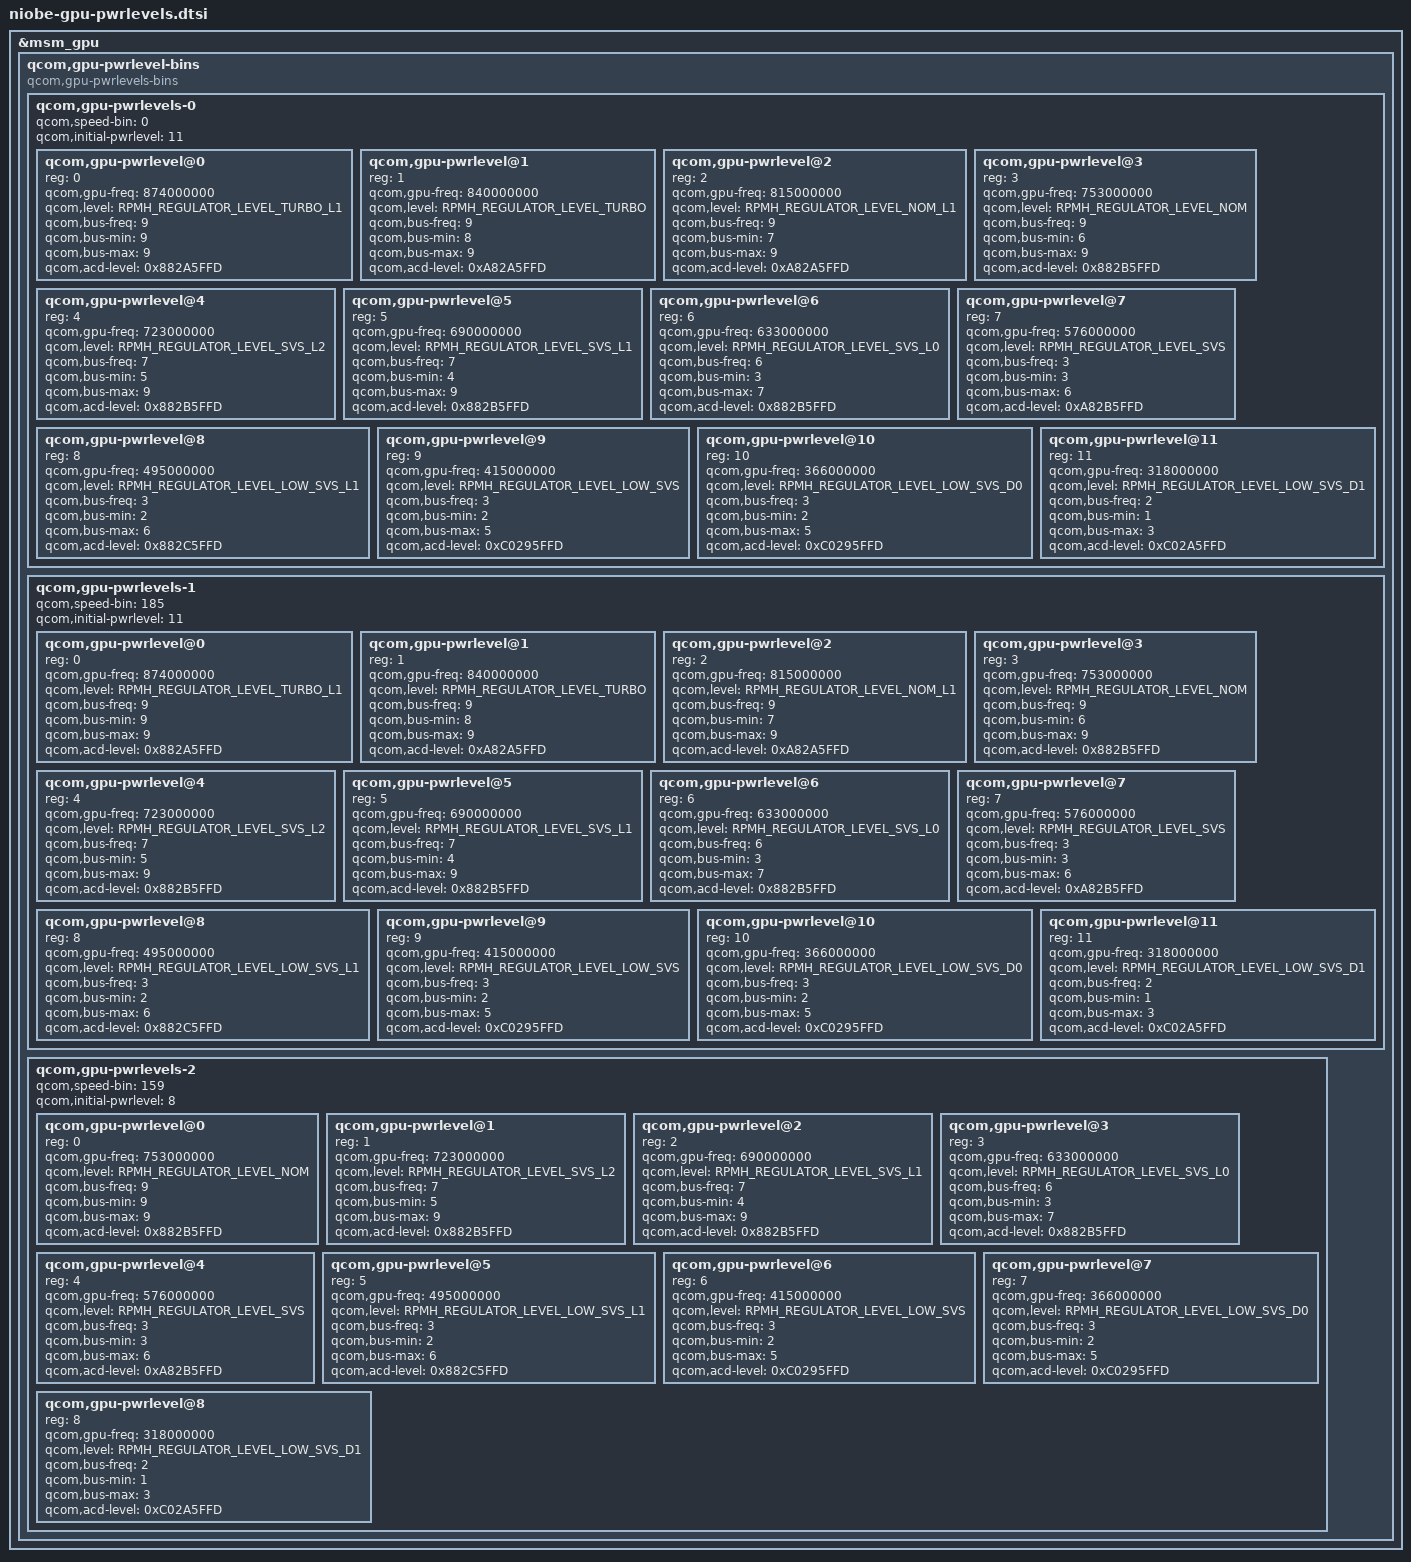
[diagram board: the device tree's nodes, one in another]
&msm_gpu {
	/* Power levels */
	qcom,gpu-pwrlevel-bins {
		#address-cells = <1>;
		#size-cells = <0>;

		compatible = "qcom,gpu-pwrlevels-bins";

		qcom,gpu-pwrlevels-0 {
			#address-cells = <1>;
			#size-cells = <0>;

			qcom,speed-bin = <0>;
			qcom,initial-pwrlevel = <11>;

			/* TURBO_L1 */
			qcom,gpu-pwrlevel@0 {
				reg = <0>;
				qcom,gpu-freq = <874000000>;
				qcom,level = <RPMH_REGULATOR_LEVEL_TURBO_L1>;

				qcom,bus-freq = <9>;
				qcom,bus-min = <9>;
				qcom,bus-max = <9>;

				qcom,acd-level = <0x882A5FFD>;
			};

			/* TURBO */
			qcom,gpu-pwrlevel@1 {
				reg = <1>;
				qcom,gpu-freq = <840000000>;
				qcom,level = <RPMH_REGULATOR_LEVEL_TURBO>;

				qcom,bus-freq = <9>;
				qcom,bus-min = <8>;
				qcom,bus-max = <9>;

				qcom,acd-level = <0xA82A5FFD>;
			};

			/* NOM_L1 */
			qcom,gpu-pwrlevel@2 {
				reg = <2>;
				qcom,gpu-freq = <815000000>;
				qcom,level = <RPMH_REGULATOR_LEVEL_NOM_L1>;

				qcom,bus-freq = <9>;
				qcom,bus-min = <7>;
				qcom,bus-max = <9>;

				qcom,acd-level = <0xA82A5FFD>;
			};

			/* NOM */
			qcom,gpu-pwrlevel@3 {
				reg = <3>;
				qcom,gpu-freq = <753000000>;
				qcom,level = <RPMH_REGULATOR_LEVEL_NOM>;

				qcom,bus-freq = <9>;
				qcom,bus-min = <6>;
				qcom,bus-max = <9>;

				qcom,acd-level = <0x882B5FFD>;
			};

			/* SVS_L2 */
			qcom,gpu-pwrlevel@4 {
				reg = <4>;
				qcom,gpu-freq = <723000000>;
				qcom,level = <RPMH_REGULATOR_LEVEL_SVS_L2>;

				qcom,bus-freq = <7>;
				qcom,bus-min = <5>;
				qcom,bus-max = <9>;

				qcom,acd-level = <0x882B5FFD>;
			};

			/* SVS_L1 */
			qcom,gpu-pwrlevel@5 {
				reg = <5>;
				qcom,gpu-freq = <690000000>;
				qcom,level = <RPMH_REGULATOR_LEVEL_SVS_L1>;

				qcom,bus-freq = <7>;
				qcom,bus-min = <4>;
				qcom,bus-max = <9>;

				qcom,acd-level = <0x882B5FFD>;
			};

			/* SVS_L0 */
			qcom,gpu-pwrlevel@6 {
				reg = <6>;
				qcom,gpu-freq = <633000000>;
				qcom,level = <RPMH_REGULATOR_LEVEL_SVS_L0>;

				qcom,bus-freq = <6>;
				qcom,bus-min = <3>;
				qcom,bus-max = <7>;

				qcom,acd-level = <0x882B5FFD>;
			};

			/* SVS */
			qcom,gpu-pwrlevel@7 {
				reg = <7>;
				qcom,gpu-freq = <576000000>;
				qcom,level = <RPMH_REGULATOR_LEVEL_SVS>;

				qcom,bus-freq = <3>;
				qcom,bus-min = <3>;
				qcom,bus-max = <6>;

				qcom,acd-level = <0xA82B5FFD>;
			};

			/* Low_SVS_L1 */
			qcom,gpu-pwrlevel@8 {
				reg = <8>;
				qcom,gpu-freq = <495000000>;
				qcom,level = <RPMH_REGULATOR_LEVEL_LOW_SVS_L1>;

				qcom,bus-freq = <3>;
				qcom,bus-min = <2>;
				qcom,bus-max = <6>;

				qcom,acd-level = <0x882C5FFD>;
			};

			/* Low_SVS */
			qcom,gpu-pwrlevel@9 {
				reg = <9>;
				qcom,gpu-freq = <415000000>;
				qcom,level = <RPMH_REGULATOR_LEVEL_LOW_SVS>;

				qcom,bus-freq = <3>;
				qcom,bus-min = <2>;
				qcom,bus-max = <5>;

				qcom,acd-level = <0xC0295FFD>;
			};

			/* Low_SVS_D0 */
			qcom,gpu-pwrlevel@10 {
				reg = <10>;
				qcom,gpu-freq = <366000000>;
				qcom,level = <RPMH_REGULATOR_LEVEL_LOW_SVS_D0>;

				qcom,bus-freq = <3>;
				qcom,bus-min = <2>;
				qcom,bus-max = <5>;

				qcom,acd-level = <0xC0295FFD>;
			};

			/* Low_SVS_D1 */
			qcom,gpu-pwrlevel@11 {
				reg = <11>;
				qcom,gpu-freq = <318000000>;
				qcom,level = <RPMH_REGULATOR_LEVEL_LOW_SVS_D1>;

				qcom,bus-freq = <2>;
				qcom,bus-min = <1>;
				qcom,bus-max = <3>;

				qcom,acd-level = <0xC02A5FFD>;
			};
		};

		qcom,gpu-pwrlevels-1 {
			#address-cells = <1>;
			#size-cells = <0>;

			qcom,speed-bin = <185>;
			qcom,initial-pwrlevel = <11>;

			/* TURBO_L1 */
			qcom,gpu-pwrlevel@0 {
				reg = <0>;
				qcom,gpu-freq = <874000000>;
				qcom,level = <RPMH_REGULATOR_LEVEL_TURBO_L1>;

				qcom,bus-freq = <9>;
				qcom,bus-min = <9>;
				qcom,bus-max = <9>;

				qcom,acd-level = <0x882A5FFD>;
			};

			/* TURBO */
			qcom,gpu-pwrlevel@1 {
				reg = <1>;
				qcom,gpu-freq = <840000000>;
				qcom,level = <RPMH_REGULATOR_LEVEL_TURBO>;

				qcom,bus-freq = <9>;
				qcom,bus-min = <8>;
				qcom,bus-max = <9>;

				qcom,acd-level = <0xA82A5FFD>;
			};

			/* NOM_L1 */
			qcom,gpu-pwrlevel@2 {
				reg = <2>;
				qcom,gpu-freq = <815000000>;
				qcom,level = <RPMH_REGULATOR_LEVEL_NOM_L1>;

				qcom,bus-freq = <9>;
				qcom,bus-min = <7>;
				qcom,bus-max = <9>;

				qcom,acd-level = <0xA82A5FFD>;
			};

			/* NOM */
			qcom,gpu-pwrlevel@3 {
				reg = <3>;
				qcom,gpu-freq = <753000000>;
				qcom,level = <RPMH_REGULATOR_LEVEL_NOM>;

				qcom,bus-freq = <9>;
				qcom,bus-min = <6>;
				qcom,bus-max = <9>;

				qcom,acd-level = <0x882B5FFD>;
			};

			/* SVS_L2 */
			qcom,gpu-pwrlevel@4 {
				reg = <4>;
				qcom,gpu-freq = <723000000>;
				qcom,level = <RPMH_REGULATOR_LEVEL_SVS_L2>;

				qcom,bus-freq = <7>;
				qcom,bus-min = <5>;
				qcom,bus-max = <9>;

				qcom,acd-level = <0x882B5FFD>;
			};

			/* SVS_L1 */
			qcom,gpu-pwrlevel@5 {
				reg = <5>;
				qcom,gpu-freq = <690000000>;
				qcom,level = <RPMH_REGULATOR_LEVEL_SVS_L1>;

				qcom,bus-freq = <7>;
				qcom,bus-min = <4>;
				qcom,bus-max = <9>;

				qcom,acd-level = <0x882B5FFD>;
			};

			/* SVS_L0 */
			qcom,gpu-pwrlevel@6 {
				reg = <6>;
				qcom,gpu-freq = <633000000>;
				qcom,level = <RPMH_REGULATOR_LEVEL_SVS_L0>;

				qcom,bus-freq = <6>;
				qcom,bus-min = <3>;
				qcom,bus-max = <7>;

				qcom,acd-level = <0x882B5FFD>;
			};

			/* SVS */
			qcom,gpu-pwrlevel@7 {
				reg = <7>;
				qcom,gpu-freq = <576000000>;
				qcom,level = <RPMH_REGULATOR_LEVEL_SVS>;

				qcom,bus-freq = <3>;
				qcom,bus-min = <3>;
				qcom,bus-max = <6>;

				qcom,acd-level = <0xA82B5FFD>;
			};

			/* Low_SVS_L1 */
			qcom,gpu-pwrlevel@8 {
				reg = <8>;
				qcom,gpu-freq = <495000000>;
				qcom,level = <RPMH_REGULATOR_LEVEL_LOW_SVS_L1>;

				qcom,bus-freq = <3>;
				qcom,bus-min = <2>;
				qcom,bus-max = <6>;

				qcom,acd-level = <0x882C5FFD>;
			};

			/* Low_SVS */
			qcom,gpu-pwrlevel@9 {
				reg = <9>;
				qcom,gpu-freq = <415000000>;
				qcom,level = <RPMH_REGULATOR_LEVEL_LOW_SVS>;

				qcom,bus-freq = <3>;
				qcom,bus-min = <2>;
				qcom,bus-max = <5>;

				qcom,acd-level = <0xC0295FFD>;
			};

			/* Low_SVS_D0 */
			qcom,gpu-pwrlevel@10 {
				reg = <10>;
				qcom,gpu-freq = <366000000>;
				qcom,level = <RPMH_REGULATOR_LEVEL_LOW_SVS_D0>;

				qcom,bus-freq = <3>;
				qcom,bus-min = <2>;
				qcom,bus-max = <5>;

				qcom,acd-level = <0xC0295FFD>;
			};

			/* Low_SVS_D1 */
			qcom,gpu-pwrlevel@11 {
				reg = <11>;
				qcom,gpu-freq = <318000000>;
				qcom,level = <RPMH_REGULATOR_LEVEL_LOW_SVS_D1>;

				qcom,bus-freq = <2>;
				qcom,bus-min = <1>;
				qcom,bus-max = <3>;

				qcom,acd-level = <0xC02A5FFD>;
			};
		};

		qcom,gpu-pwrlevels-2 {
			#address-cells = <1>;
			#size-cells = <0>;

			qcom,speed-bin = <159>;
			qcom,initial-pwrlevel = <8>;

			/* NOM */
			qcom,gpu-pwrlevel@0 {
				reg = <0>;
				qcom,gpu-freq = <753000000>;
				qcom,level = <RPMH_REGULATOR_LEVEL_NOM>;

				qcom,bus-freq = <9>;
				qcom,bus-min = <9>;
				qcom,bus-max = <9>;

				qcom,acd-level = <0x882B5FFD>;
			};

			/* SVS_L2 */
			qcom,gpu-pwrlevel@1 {
				reg = <1>;
				qcom,gpu-freq = <723000000>;
				qcom,level = <RPMH_REGULATOR_LEVEL_SVS_L2>;

				qcom,bus-freq = <7>;
				qcom,bus-min = <5>;
				qcom,bus-max = <9>;

				qcom,acd-level = <0x882B5FFD>;
			};

			/* SVS_L1 */
			qcom,gpu-pwrlevel@2 {
				reg = <2>;
				qcom,gpu-freq = <690000000>;
				qcom,level = <RPMH_REGULATOR_LEVEL_SVS_L1>;

				qcom,bus-freq = <7>;
				qcom,bus-min = <4>;
				qcom,bus-max = <9>;

				qcom,acd-level = <0x882B5FFD>;
			};

			/* SVS_L0 */
			qcom,gpu-pwrlevel@3 {
				reg = <3>;
				qcom,gpu-freq = <633000000>;
				qcom,level = <RPMH_REGULATOR_LEVEL_SVS_L0>;

				qcom,bus-freq = <6>;
				qcom,bus-min = <3>;
				qcom,bus-max = <7>;

				qcom,acd-level = <0x882B5FFD>;
			};

			/* SVS */
			qcom,gpu-pwrlevel@4 {
				reg = <4>;
				qcom,gpu-freq = <576000000>;
				qcom,level = <RPMH_REGULATOR_LEVEL_SVS>;

				qcom,bus-freq = <3>;
				qcom,bus-min = <3>;
				qcom,bus-max = <6>;

				qcom,acd-level = <0xA82B5FFD>;
			};

			/* Low_SVS_L1 */
			qcom,gpu-pwrlevel@5 {
				reg = <5>;
				qcom,gpu-freq = <495000000>;
				qcom,level = <RPMH_REGULATOR_LEVEL_LOW_SVS_L1>;

				qcom,bus-freq = <3>;
				qcom,bus-min = <2>;
				qcom,bus-max = <6>;

				qcom,acd-level = <0x882C5FFD>;
			};

			/* Low_SVS */
			qcom,gpu-pwrlevel@6 {
				reg = <6>;
				qcom,gpu-freq = <415000000>;
				qcom,level = <RPMH_REGULATOR_LEVEL_LOW_SVS>;

				qcom,bus-freq = <3>;
				qcom,bus-min = <2>;
				qcom,bus-max = <5>;

				qcom,acd-level = <0xC0295FFD>;
			};

			/* Low_SVS_D0 */
			qcom,gpu-pwrlevel@7 {
				reg = <7>;
				qcom,gpu-freq = <366000000>;
				qcom,level = <RPMH_REGULATOR_LEVEL_LOW_SVS_D0>;

				qcom,bus-freq = <3>;
				qcom,bus-min = <2>;
				qcom,bus-max = <5>;

				qcom,acd-level = <0xC0295FFD>;
			};

			/* Low_SVS_D1 */
			qcom,gpu-pwrlevel@8 {
				reg = <8>;
				qcom,gpu-freq = <318000000>;
				qcom,level = <RPMH_REGULATOR_LEVEL_LOW_SVS_D1>;

				qcom,bus-freq = <2>;
				qcom,bus-min = <1>;
				qcom,bus-max = <3>;

				qcom,acd-level = <0xC02A5FFD>;
			};
		};
	};
};
